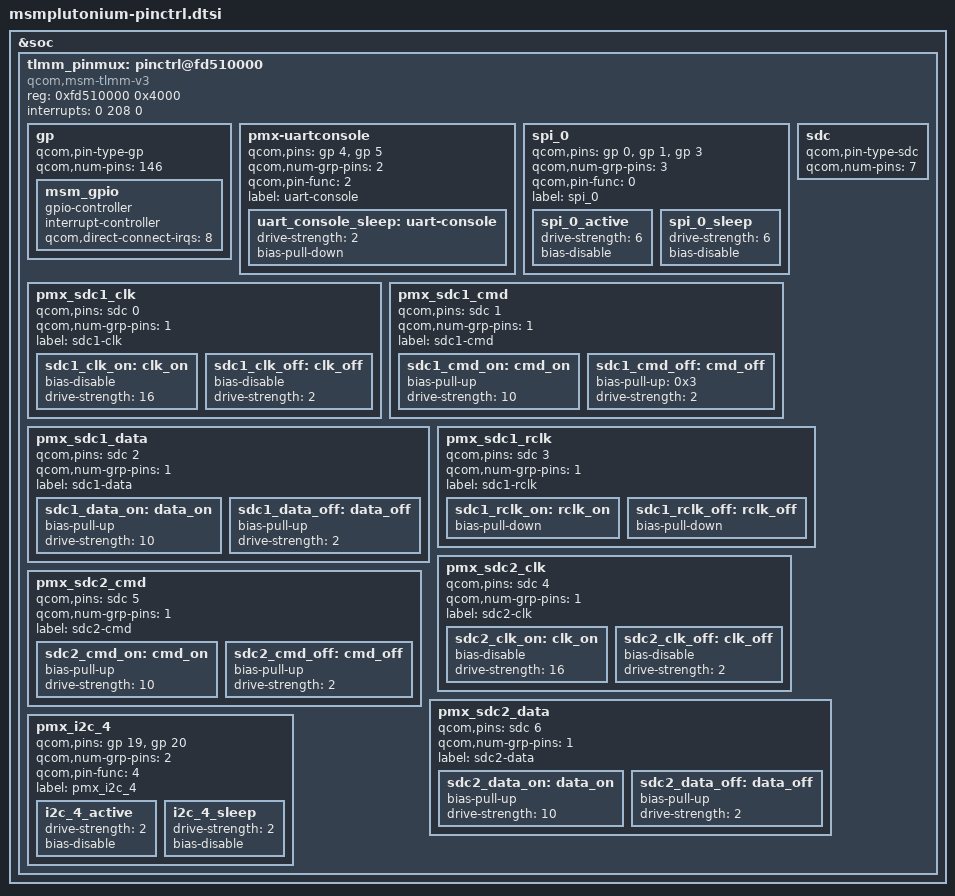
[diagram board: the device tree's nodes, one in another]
/* Copyright (c) 2013-2014, The Linux Foundation. All rights reserved.
 *
 * This program is free software; you can redistribute it and/or modify
 * it under the terms of the GNU General Public License version 2 and
 * only version 2 as published by the Free Software Foundation.
 *
 * This program is distributed in the hope that it will be useful,
 * but WITHOUT ANY WARRANTY; without even the implied warranty of
 * MERCHANTABILITY or FITNESS FOR A PARTICULAR PURPOSE.  See the
 * GNU General Public License for more details.
 */

&soc {
	tlmm_pinmux: pinctrl@fd510000 {
		compatible = "qcom,msm-tlmm-v3";
		reg = <0xfd510000 0x4000>;
		interrupts = <0 208 0>;

		/*General purpose pins*/
		gp: gp {
			qcom,pin-type-gp;
			qcom,num-pins = <146>;
			#qcom,pin-cells = <1>;

			msm_gpio: msm_gpio {
				gpio-controller;
				#gpio-cells = <2>;
				interrupt-controller;
				#interrupt-cells = <2>;
				qcom,direct-connect-irqs = <8>;
			};
		};

		pmx-uartconsole {
			qcom,pins = <&gp 4>, <&gp 5>;
			qcom,num-grp-pins = <2>;
			qcom,pin-func = <2>;
			label = "uart-console";

		uart_console_sleep: uart-console {
				drive-strength = <2>;
				bias-pull-down;
			};
		};

		spi_0 {
			qcom,pins = <&gp 0>, <&gp 1>, <&gp 3>;
			qcom,num-grp-pins = <3>;
			qcom,pin-func = <0>;
			label = "spi_0";

			spi_0_active: spi_0_active {
					       drive-strength = <6>;
					       bias-disable;
		        };

			spi_0_sleep: spi_0_sleep {
					       drive-strength = <6>;
					       bias-disable;
		        };
		};

		/* SDC pin type */
		sdc: sdc {
			qcom,pin-type-sdc;
			/* 0-3 for sdc1 4-6 for sdc2 */
			qcom,num-pins = <7>;
			/* Order of pins */
			/* SDC1: CLK -> 0, CMD -> 1, DATA -> 2, RCLK -> 3 */
			/* SDC2: CLK -> 4, CMD -> 5, DATA -> 6 */
			#qcom,pin-cells = <1>;
		};

		pmx_sdc1_clk {
			qcom,pins = <&sdc 0>;
			qcom,num-grp-pins = <1>;
			label = "sdc1-clk";
			sdc1_clk_on: clk_on {
				bias-disable; /* NO pull */
				drive-strength = <16>; /* 16 MA */
			};
			sdc1_clk_off: clk_off {
				bias-disable; /* NO pull */
				drive-strength = <2>; /* 2 MA */
			};
		};

		pmx_sdc1_cmd {
			qcom,pins = <&sdc 1>;
			qcom,num-grp-pins = <1>;
			label = "sdc1-cmd";
			sdc1_cmd_on: cmd_on {
				bias-pull-up; /* pull up */
				drive-strength = <10>; /* 10 MA */
			};
			sdc1_cmd_off: cmd_off {
				bias-pull-up = <0x3>; /* pull up */
				drive-strength = <2>; /* 2 MA */
			};
		};

		pmx_sdc1_data {
			qcom,pins = <&sdc 2>;
			qcom,num-grp-pins = <1>;
			label = "sdc1-data";
			sdc1_data_on: data_on {
				bias-pull-up; /* pull up */
				drive-strength = <10>; /* 10 MA */
			};
			sdc1_data_off: data_off {
				bias-pull-up; /* pull up */
				drive-strength = <2>; /* 2 MA */
			};
		};

		pmx_sdc1_rclk {
			qcom,pins = <&sdc 3>;
			qcom,num-grp-pins = <1>;
			label = "sdc1-rclk";
			sdc1_rclk_on: rclk_on {
				bias-pull-down; /* pull down */
			};
			sdc1_rclk_off: rclk_off {
				bias-pull-down; /* pull down */
			};
		};

		pmx_sdc2_clk {
			qcom,pins = <&sdc 4>;
			qcom,num-grp-pins = <1>;
			label = "sdc2-clk";
			sdc2_clk_on: clk_on {
				bias-disable; /* NO pull */
				drive-strength = <16>; /* 16 MA */
			};
			sdc2_clk_off: clk_off {
				bias-disable; /* NO pull */
				drive-strength = <2>; /* 2 MA */
			};
		};

		pmx_sdc2_cmd {
			qcom,pins = <&sdc 5>;
			qcom,num-grp-pins = <1>;
			label = "sdc2-cmd";
			sdc2_cmd_on: cmd_on {
				bias-pull-up; /* pull up */
				drive-strength = <10>; /* 10 MA */
			};
			sdc2_cmd_off: cmd_off {
				bias-pull-up; /* pull up */
				drive-strength = <2>; /* 2 MA */
			};
		};

		pmx_sdc2_data {
			qcom,pins = <&sdc 6>;
			qcom,num-grp-pins = <1>;
			label = "sdc2-data";
			sdc2_data_on: data_on {
				bias-pull-up; /* pull up */
				drive-strength = <10>; /* 10 MA */
			};
			sdc2_data_off: data_off {
				bias-pull-up; /* pull up */
				drive-strength = <2>; /* 2 MA */
			};
		};

		pmx_i2c_4 {
			qcom,pins = <&gp 19>, <&gp 20>;
			qcom,num-grp-pins = <2>;
			qcom,pin-func = <4>;
			label = "pmx_i2c_4";

			i2c_4_active: i2c_4_active {
				drive-strength = <2>;
				bias-disable;
			};

			i2c_4_sleep: i2c_4_sleep {
				drive-strength = <2>;
				bias-disable;
			};
		};
	};
};
